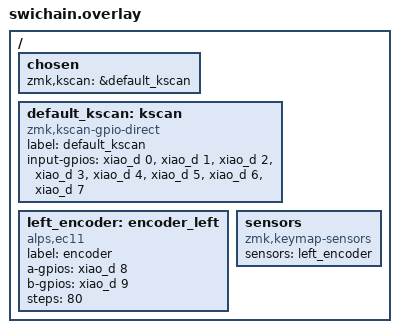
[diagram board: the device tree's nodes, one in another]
#include <zephyr/dt-bindings/led/led.h>
#include <zephyr/dt-bindings/gpio/gpio.h>

/ {
    chosen {
        zmk,kscan = &default_kscan;
    };

    default_kscan: kscan {
        compatible = "zmk,kscan-gpio-direct";
        label = "default_kscan";

        input-gpios =
            <&xiao_d 0 (GPIO_ACTIVE_HIGH | GPIO_PULL_UP)>,
            <&xiao_d 1 (GPIO_ACTIVE_HIGH | GPIO_PULL_UP)>,
            <&xiao_d 2 (GPIO_ACTIVE_HIGH | GPIO_PULL_UP)>,
            <&xiao_d 3 (GPIO_ACTIVE_HIGH | GPIO_PULL_UP)>,
            <&xiao_d 4 (GPIO_ACTIVE_HIGH | GPIO_PULL_UP)>,
            <&xiao_d 5 (GPIO_ACTIVE_HIGH | GPIO_PULL_UP)>,
            <&xiao_d 6 (GPIO_ACTIVE_HIGH | GPIO_PULL_UP)>,
            <&xiao_d 7 (GPIO_ACTIVE_HIGH | GPIO_PULL_UP)>;
    };

    left_encoder: encoder_left {
        compatible = "alps,ec11";
        label = "encoder";
        a-gpios = <&xiao_d 8 (GPIO_ACTIVE_HIGH | GPIO_PULL_UP)>;
        b-gpios = <&xiao_d 9 (GPIO_ACTIVE_HIGH | GPIO_PULL_UP)>;
        steps = <80>;
        status = "okay";
    };

    sensors {
        compatible = "zmk,keymap-sensors";
        sensors = <&left_encoder>;
    };
};

//led_strip: ws2812b_strip {
//    compatible = "worldsemi,ws2812b-gpio";
//    label = "LED Strip";
//    gpios = <&xiao_d 10 GPIO_ACTIVE_HIGH>;
//    chain-length = <6>;
//    color-mapping = <LED_COLOR_ID_GREEN LED_COLOR_ID_RED LED_COLOR_ID_BLUE>;
//};
